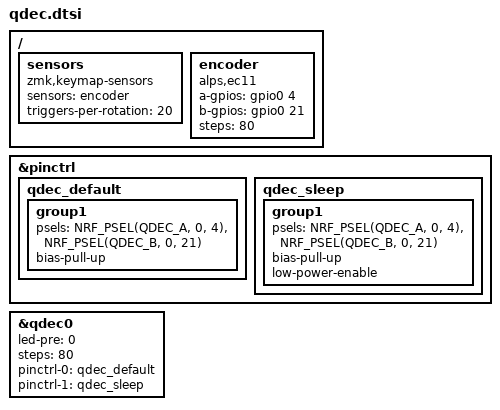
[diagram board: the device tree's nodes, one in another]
/*
 * copyright (c) 2025 ZMK project contributors
 *
 * SPDX-license-identifier: MIT
 */

/ {
    sensors: sensors {
        compatible = "zmk,keymap-sensors";
        sensors = <&encoder>;
        triggers-per-rotation = <20>;
    };

    encoder: encoder {
        compatible = "alps,ec11";
        a-gpios = <&gpio0 4  (GPIO_ACTIVE_HIGH | GPIO_PULL_UP)>;
        b-gpios = <&gpio0 21 (GPIO_ACTIVE_HIGH | GPIO_PULL_UP)>;
        steps = <80>;
        status = "okay";
    };
};

&pinctrl {
    qdec_default: qdec_default {
        group1 {
            psels = <NRF_PSEL(QDEC_A, 0, 4)>,
                    <NRF_PSEL(QDEC_B, 0, 21)>;
            bias-pull-up;
        };
    };

    qdec_sleep: qdec_sleep {
        group1 {
            psels = <NRF_PSEL(QDEC_A, 0, 4)>,
                    <NRF_PSEL(QDEC_B, 0, 21)>;
            bias-pull-up;
            low-power-enable;
        };
    };
};

encoder: &qdec0 {
    status = "okay";
    led-pre = <0>;
    steps = <80>;
    pinctrl-0 = <&qdec_default>;
    pinctrl-1 = <&qdec_sleep>;
    pinctrl-names = "default", "sleep";
};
